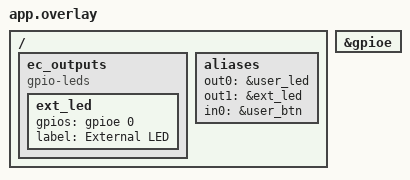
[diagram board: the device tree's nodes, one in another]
/ {
	/* LED ngoài trên PE0 (bỏ khối này nếu chỉ dùng LED LIFE) */
	ec_outputs {
		compatible = "gpio-leds";
		ext_led: ext_led {
			gpios = <&gpioe 0 GPIO_ACTIVE_HIGH>;
			label = "External LED";
		};
	};

	aliases {
		out0 = &user_led;   /* LED LIFE PA8 – đã có trong board DTS */
		out1 = &ext_led;    /* LED ngoài PE0 */
		in0  = &user_btn;   /* Nút PA10 – đã có trong board DTS (pull-up, active low) */
	};
};

&gpioe { status = "okay"; };   /* board chỉ bật gpioa..gpiod */
